# max32620 register map
Vendor: Maxim Integrated; Series: ARMCM4; File version: 1.1
CPU: CM4 r1p0, little endian, no MPU, FPU, 3 interrupt priority bits
Registers are 32-bit, read-write, reset 0x0 unless marked. A register's access mark holds for its fields unless they carry their own. Offsets are from the block's base; [hi:lo] are bit positions; {n}, {i} and the like mark numbered series.

## TMR0 — 16/32 bit Timer/Counters
Base 0x4000B000
Same registers: TMR1 0x4000C000, TMR2 0x4000D000, TMR3 0x4000E000, TMR4 0x4000F000, TMR5 0x40010000
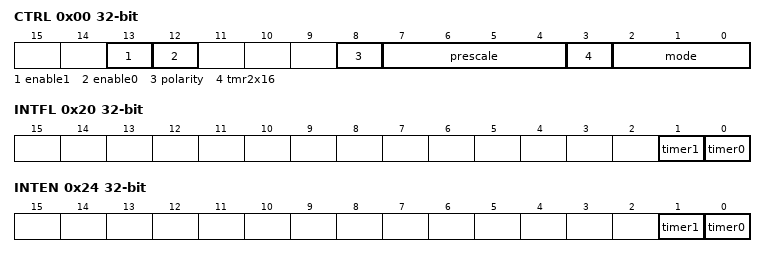
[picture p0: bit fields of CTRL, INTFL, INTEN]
0x00 CTRL — Timer Control Register
  [13] enable1 — Enable 16-bit timer 1
  [12] enable0 — Enable 32-bit timer / 16-bit timer 0
  [8] polarity — Timer I/O Polarity
  [7:4] prescale — Timer Clock Prescale Setting
  [3] tmr2x16 — Dual 16-bit Timer Mode
  [2:0] mode — Operating Modes for 32-bit/16-bit Timers
0x04 COUNT32 — [32 bit] Current Count Value
0x08 TERM_CNT32 — [32 bit] Terminal Count Setting
0x0C PWM_CAP32 — [32 bit] PWM Compare Setting or Capture/Measure Value
0x10 COUNT16_0 — [16 bit] Current Count Value, 16-bit Timer 0
  [15:0] value — Count Value
0x14 TERM_CNT16_0 — [16 bit] Terminal Count Setting, 16-bit Timer 0
  [15:0] term_count — Terminal Count Setting
0x18 COUNT16_1 — [16 bit] Current Count Value, 16-bit Timer 1
  [15:0] value — Count Value
0x1C TERM_CNT16_1 — [16 bit] Terminal Count Setting, 16-bit Timer 1
  [15:0] term_count — Terminal Count Setting
0x20 INTFL — Timer Module Interrupt Flags
  [1] timer1 write-1-clears — Interrupt Flag for 16-bit Timer 1
  [0] timer0 write-1-clears — Interrupt Flag for 32-bit Timer / 16-bit Timer 0
0x24 INTEN — Timer Module Interrupt Enable/Disable Settings
  [1] timer1 — Interrupt Enable for 16-bit Timer 1
  [0] timer0 — Interrupt Enable for 32-bit Timer / 16-bit Timer 0

## PTG — Pulse Train Generation
Base 0x40011000
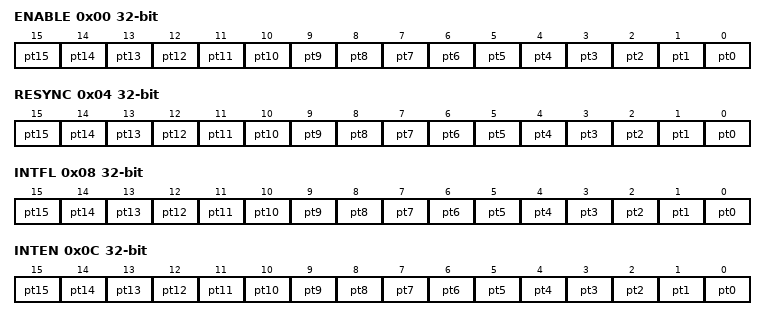
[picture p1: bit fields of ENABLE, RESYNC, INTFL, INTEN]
0x00 ENABLE — Global Enable/Disable Controls for All Pulse Trains
  [n] pt{n} (n=0..15) — Enable/Disable control for PT{n}
0x04 RESYNC — Global Resync (All Pulse Trains) Control
  [n] pt{n} (n=0..15) — Resync control for PT{n}
0x08 INTFL — Pulse Train Interrupt Flags
  [n] pt{n} (n=0..15) — Pulse Train {n} Stopped Interrupt Flag
0x0C INTEN — Pulse Train Interrupt Enable/Disable
  [n] pt{n} (n=0..15) — Pulse Train {n} Stopped Interrupt Enable/Disable

## PT0 — Pulse Train Generation
Base 0x40011010
Same registers: PT{n} {0x40011010+0xC*n} (n=1..15)
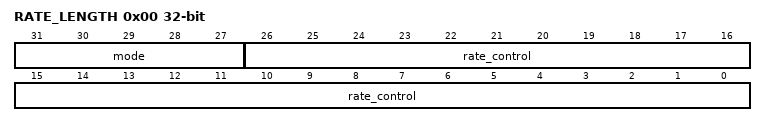
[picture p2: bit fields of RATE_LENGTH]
0x00 RATE_LENGTH — Pulse Train Configuration
  [31:27] mode — Pulse Train Output Mode/Train Length
    0=32_BIT (Pulse train, 32 bit pattern.); 1=SQUARE_WAVE (Square wave mode.); {v}={v}_BIT (Pulse train, {v} bit pattern.) (v=2..31)
  [26:0] rate_control — Pulse Train Enable/Rate Control
0x04 TRAIN — Pulse Train Output Pattern
0x08 LOOP — Pulse Train Loop Count

## UART0 — UART / Serial Port Interface
Base 0x40012000
Same registers: UART1 0x40013000, UART2 0x40014000, UART3 0x40015000
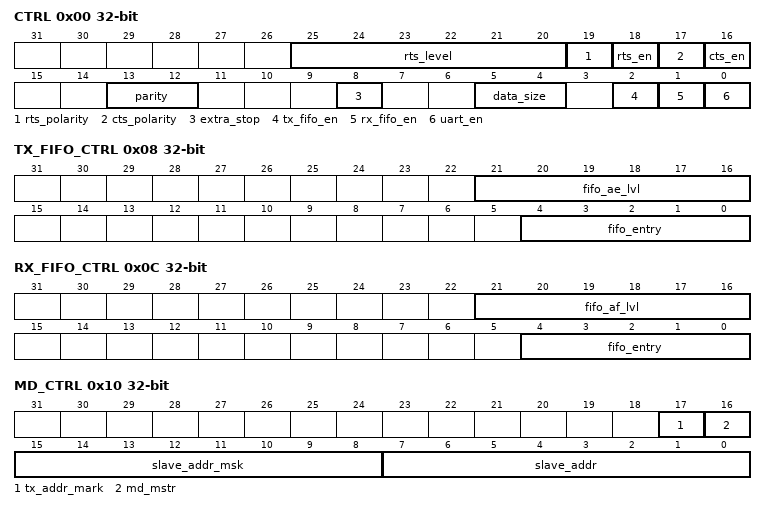
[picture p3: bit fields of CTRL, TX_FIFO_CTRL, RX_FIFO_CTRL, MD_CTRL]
0x00 CTRL — UART Control Register
  [25:20] rts_level — RX FIFO LTE Level for RTS Assert
  [19] rts_polarity
  [18] rts_en — RTS Enable
  [17] cts_polarity
  [16] cts_en — CTS Enable
  [13:12] parity — Parity Mode
  [8] extra_stop — Extra Stop Enable
  [5:4] data_size
  [2] tx_fifo_en — TX FIFO Enable
  [1] rx_fifo_en — RX FIFO Enable
  [0] uart_en — UART Enable
0x04 BAUD — UART Baud Control Register
  [7:0] baud_divisor
0x08 TX_FIFO_CTRL — UART TX Fifo Control Register
  [21:16] fifo_ae_lvl — TX FIFO AE Level
  [4:0] fifo_entry ro — TX FIFO Entries
0x0C RX_FIFO_CTRL — UART RX Fifo Control Register
  [21:16] fifo_af_lvl — RX FIFO AF Level
  [4:0] fifo_entry ro — RX FIFO Entries
0x10 MD_CTRL — UART Multidrop Control Register
  [17] tx_addr_mark — RX Address Mark
  [16] md_mstr — Multidrop Master
  [15:8] slave_addr_msk — Slave Address Mask
  [7:0] slave_addr — Slave Address
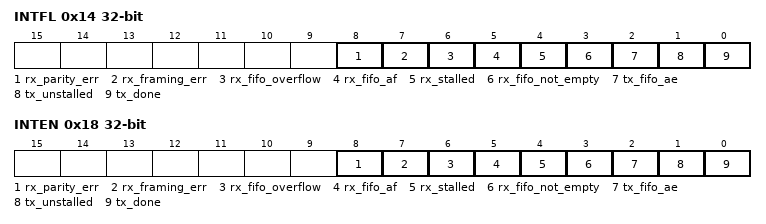
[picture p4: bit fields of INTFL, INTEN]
0x14 INTFL — UART Interrupt Flags
  [8] rx_parity_err write-1-clears — RX Parity Error Interrupt Flag
  [7] rx_framing_err write-1-clears — RX Framing Error Interrupt Flag
  [6] rx_fifo_overflow write-1-clears — RX FIFO Overflow Interrupt Flag
  [5] rx_fifo_af write-1-clears — RX FIFO Almost Full Interrupt Flag
  [4] rx_stalled write-1-clears — RX Stalled Interrupt Flag
  [3] rx_fifo_not_empty write-1-clears — RX FIFO Not Empty Interrupt Flag
  [2] tx_fifo_ae write-1-clears — TX FIFO Almost Empty Interrupt Flag
  [1] tx_unstalled write-1-clears — TX Unstalled Interrupt Flag
  [0] tx_done write-1-clears — TX Done Interrupt Flag
0x18 INTEN — UART Interrupt Enable/Disable Controls
  [8] rx_parity_err — RX Parity Error Interrupt Enable/Disable
  [7] rx_framing_err — RX Framing Error Interrupt Enable/Disable
  [6] rx_fifo_overflow — RX FIFO Overflow Interrupt Enable/Disable
  [5] rx_fifo_af — RX FIFO Almost Full Interrupt Enable/Disable
  [4] rx_stalled — RX Stalled Interrupt Enable/Disable
  [3] rx_fifo_not_empty — RX FIFO Not Empty Interrupt Enable/Disable
  [2] tx_fifo_ae — TX FIFO Almost Empty Interrupt Enable/Disable
  [1] tx_unstalled — TX Unstalled Interrupt Enable/Disable
  [0] tx_done — TX Done Interrupt Enable/Disable
